# CH32V205 register map
Vendor: WCH Ltd.; File version: 1.0
Registers are 32-bit, read-write, reset 0x0 unless marked. A register's access mark holds for its fields unless they carry their own. Offsets are from the block's base; [hi:lo] are bit positions; {n}, {i} and the like mark numbered series; 'fields as' and 'values as' point back to an identical list.

## DMA1 — DMA1 controller
Base 0x40020000
Same registers: DMA2 0x40020400
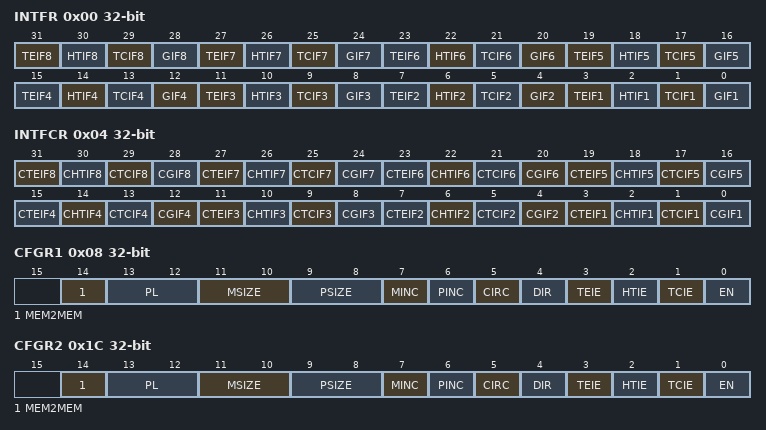
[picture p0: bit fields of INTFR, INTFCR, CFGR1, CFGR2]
0x00 INTFR ro — DMA interrupt status register (DMA_INTFR)
  [31] TEIF8 — Channel 8 Transfer Error flag use in ch32v20_D8/D8W/D6
  [30] HTIF8 — Channel 8 Half Transfer Complete flag use in ch32v20_D8/D8W/D6
  [29] TCIF8 — Channel 8 Transfer Complete flag use in ch32v20_D8/D8W/D6
  [28] GIF8 — Channel 8 Global interrupt flag use in ch32v20_D8/D8W/D6
  [4n-1] TEIF{n} (n=1..7) — Channel {n} Transfer Error flag
  [4n-2] HTIF{n} (n=1..7) — Channel {n} Half Transfer Complete flag
  [4n-3] TCIF{n} (n=1..7) — Channel {n} Transfer Complete flag
  [4n-4] GIF{n} (n=1..7) — Channel {n} Global interrupt flag
0x04 INTFCR wo — DMA interrupt flag clear register (DMA_INTFCR)
  [31] CTEIF8 — Channel 8 Transfer Error clear use in ch32v20_D8/D8W/D6
  [30] CHTIF8 — Channel 8 Half Transfer clear use in ch32v20_D8/D8W/D6
  [29] CTCIF8 — Channel 8 Transfer Complete clear use in ch32v20_D8/D8W/D6
  [28] CGIF8 — Channel 8 Global interrupt clear use in ch32v20_D8/D8W/D6
  [4n-1] CTEIF{n} (n=1..7) — Channel {n} Transfer Error clear
  [4n-2] CHTIF{n} (n=1..7) — Channel {n} Half Transfer clear
  [4n-3] CTCIF{n} (n=1..7) — Channel {n} Transfer Complete clear
  [4n-4] CGIF{n} (n=1..7) — Channel {n} Global interrupt clear
0x08 CFGR1 — DMA channel configuration register (DMA_CFGR)
  [14] MEM2MEM — Memory to memory mode
  [13:12] PL — Channel Priority level
  [11:10] MSIZE — Memory size
  [9:8] PSIZE — Peripheral size
  [7] MINC — Memory increment mode
  [6] PINC — Peripheral increment mode
  [5] CIRC — Circular mode
  [4] DIR — Data transfer direction
  [3] TEIE — Transfer error interrupt enable
  [2] HTIE — Half Transfer interrupt enable
  [1] TCIE — Transfer complete interrupt enable
  [0] EN — Channel enable
0x0C CNTR1 — DMA channel 1 number of data register
  [15:0] NDT — Number of data to transfer
0x10 PADDR1 — DMA channel 1 peripheral address register
  [31:0] PA — Peripheral address
{0x0+0x14*i} MADDR{i} (i=1..7) — DMA channel {i} memory address register
  [31:0] MA — Memory address
0x18 M1ADDR1 — DMA channel 1 memory address1 register
  [31:0] M1A — Memory address
0x1C CFGR2 — DMA channel configuration register (DMA_CFGR)
  fields as CFGR1
0x20 CNTR2 — DMA channel 2 number of data register
  [15:0] NDT — Number of data to transfer
0x24 PADDR2 — DMA channel 2 peripheral address register
  [31:0] PA — Peripheral address
0x2C M1ADDR2 — DMA channel 2 memory address 1 register
  [31:0] M1A — Memory address
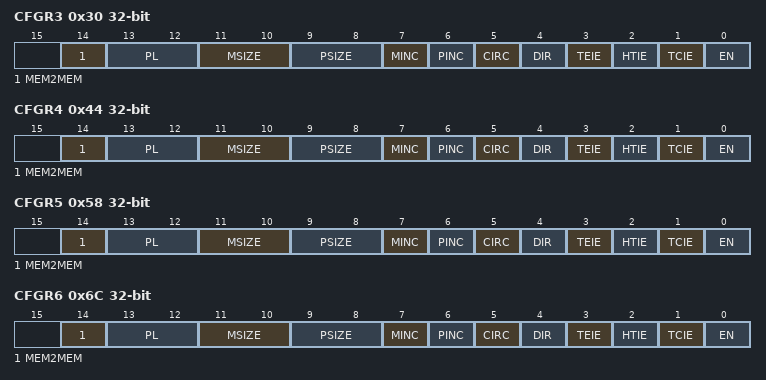
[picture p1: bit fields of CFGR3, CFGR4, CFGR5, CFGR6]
0x30 CFGR3 — DMA channel configuration register (DMA_CFGR)
  fields as CFGR1
0x34 CNTR3 — DMA channel 3 number of data register
  [15:0] NDT — Number of data to transfer
0x38 PADDR3 — DMA channel 3 peripheral address register
  [31:0] PA — Peripheral address
0x40 M1ADDR3 — DMA channel 3 memory address 1 register
  [31:0] M1A — Memory address
0x44 CFGR4 — DMA channel configuration register (DMA_CFGR)
  fields as CFGR1
0x48 CNTR4 — DMA channel 4 number of data register
  [15:0] NDT — Number of data to transfer
0x4C PADDR4 — DMA channel 4 peripheral address register
  [31:0] PA — Peripheral address
{0x4+0x14*i} M1ADDR{i} (i=4..8) — DMA channel {i} memory address 2 register
  [31:0] M1A — Memory address
0x58 CFGR5 — DMA channel configuration register (DMA_CFGR)
  fields as CFGR1
0x5C CNTR5 — DMA channel 5 number of data register
  [15:0] NDT — Number of data to transfer
0x60 PADDR5 — DMA channel 5 peripheral address register
  [31:0] PA — Peripheral address
0x6C CFGR6 — DMA channel configuration register (DMA_CFGR)
  fields as CFGR1
0x70 CNTR6 — DMA channel 6 number of data register
  [15:0] NDT — Number of data to transfer
0x74 PADDR6 — DMA channel 6 peripheral address register
  [31:0] PA — Peripheral address
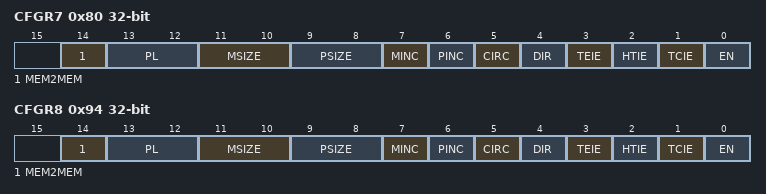
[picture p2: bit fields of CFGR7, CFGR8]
0x80 CFGR7 — DMA channel configuration register (DMA_CFGR)
  fields as CFGR1
0x84 CNTR7 — DMA channel 7 number of data register
  [15:0] NDT — Number of data to transfer
0x88 PADDR7 — DMA channel 7 peripheral address register
  [31:0] PA — Peripheral address
0x94 CFGR8 — DMA channel configuration register (DMA_CFGR) use in ch32v20_D8/D8W/D6
  fields as CFGR1
0x98 CNTR8 — DMA channel 8 number of data register use in ch32v20_D8/D8W/D6
  [15:0] NDT — Number of data to transfer
0x9C PADDR8 — DMA channel 8 peripheral address register use in ch32v20_D8/D8W/D6
  [31:0] PA — Peripheral address
0xA0 MADDR8 — DMA channel 8 memory address register use in ch32v20_D8/D8W/D6
  [31:0] MA — Memory address
